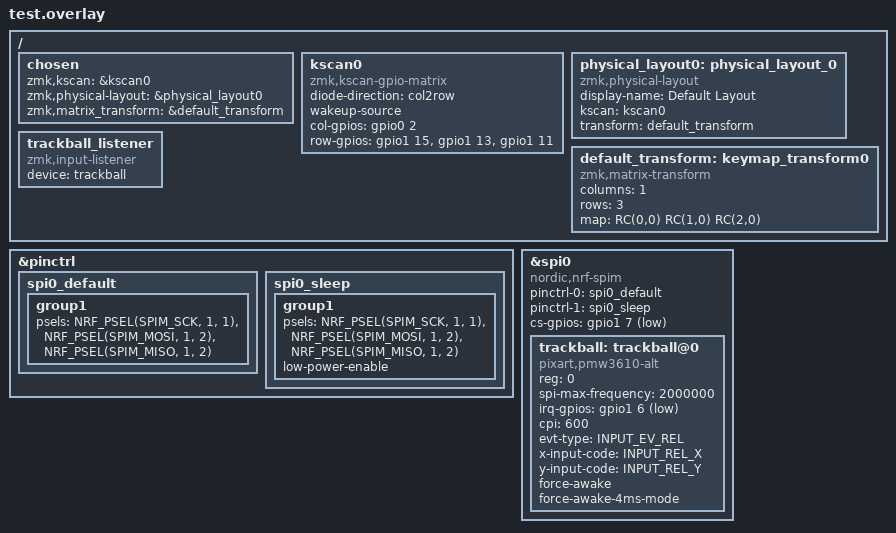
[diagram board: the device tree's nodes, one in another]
#include <dt-bindings/zmk/matrix_transform.h>

/ {
    chosen {
        zmk,kscan = &kscan0;
        zmk,physical-layout = &physical_layout0;
        zmk,matrix_transform = &default_transform;
        // Other chosen items
    };

    kscan0: kscan0 {
        compatible = "zmk,kscan-gpio-matrix";
        diode-direction = "col2row";
        wakeup-source;

        col-gpios
            = <&gpio0 2 GPIO_ACTIVE_HIGH>
            ;

        row-gpios
            = <&gpio1 15 (GPIO_ACTIVE_HIGH | GPIO_PULL_DOWN)>
            , <&gpio1 13 (GPIO_ACTIVE_HIGH | GPIO_PULL_DOWN)>
            , <&gpio1 11 (GPIO_ACTIVE_HIGH | GPIO_PULL_DOWN)>
            ;
    };

    physical_layout0: physical_layout_0 { // First physical layout, use different naming for other layouts
        compatible = "zmk,physical-layout";
        display-name = "Default Layout";
        kscan = <&kscan0>; // Label of the kscan node, optional if all layouts use the same
        transform = <&default_transform>; // Label of the matrix transform for this layout
    };

    default_transform: keymap_transform0 {
        compatible = "zmk,matrix-transform";
        columns = <1>; // Length of the "col-gpios" array
        rows = <3>; // Length of the "row-gpios" array
        map = <
        //   Key 1
            RC(0,0)
        //   Key 4
            RC(1,0)
        //   Key 7
            RC(2,0)
        >;
    };
};

&pinctrl {
    spi0_default: spi0_default {
        group1 {
            psels = <NRF_PSEL(SPIM_SCK, 1, 1)>,
                <NRF_PSEL(SPIM_MOSI, 1, 2)>,
                <NRF_PSEL(SPIM_MISO, 1, 2)>;
        };
    };

    spi0_sleep: spi0_sleep {
        group1 {
            psels = <NRF_PSEL(SPIM_SCK, 1, 1)>,
                <NRF_PSEL(SPIM_MOSI, 1, 2)>,
                <NRF_PSEL(SPIM_MISO, 1, 2)>;
            low-power-enable;
        };
    };
};

#include <zephyr/dt-bindings/input/input-event-codes.h>

&spi0 {
    status = "okay";
    compatible = "nordic,nrf-spim";
    pinctrl-0 = <&spi0_default>;
    pinctrl-1 = <&spi0_sleep>;
    pinctrl-names = "default", "sleep";
    cs-gpios = <&gpio1 7 GPIO_ACTIVE_LOW>;

    trackball: trackball@0 {
        status = "okay";
        compatible = "pixart,pmw3610-alt";
        reg = <0>;
        spi-max-frequency = <2000000>;
        irq-gpios = <&gpio1 6 (GPIO_ACTIVE_LOW | GPIO_PULL_UP)>;
        cpi = <600>;
        // swap-xy; /* optional */
        // invert-x; /* optional */
        // invert-y; /* optional */
        evt-type = <INPUT_EV_REL>;
        x-input-code = <INPUT_REL_X>;
        y-input-code = <INPUT_REL_Y>;

        force-awake;
        /* keep the sensor awake while ZMK activity state is ACTIVE,
           fallback to normal downshift mode after ZMK goes into IDLE / SLEEP mode.
           thus, the sensor would be a `wakeup-source` */

        force-awake-4ms-mode;
        /* while force-awake is acitvated, enable this mode to force sampling per
           4ms, where the default sampling rate is 8ms. */
        /* NOTE: apply this mode if you need 250Hz with direct USB connection. */
    };
};

/ {
  trackball_listener {
    compatible = "zmk,input-listener";
    device = <&trackball>;
  };
};
